AUTOSAR XML (schema 4-0-3)
package /AUTOSAR_Dem/ImplementationDataTypes
  4 x impl type, all with category=TYPE_REFERENCE, implementation-data-type=uint8:
    Dem_OperationCycleIdType: compu {0=DEM_OPCYC_IGNITION, 1=DEM_OPCYC_OBD_DCY, 2=DEM_OPCYC_POWER}, range raw 0..2
    Dem_IndicatorIdType: compu {0=DemConf_DemIndicator_DEM_INDICATOR_0}, range raw 0
    Dem_RatioIdType: range raw 0
    Dem_EnableConditionType: compu {0=DemConf_DemEnableCondition_DEM_SL_ECU_LEVEL}
package /AUTOSAR_Dem/SwComponentTypes
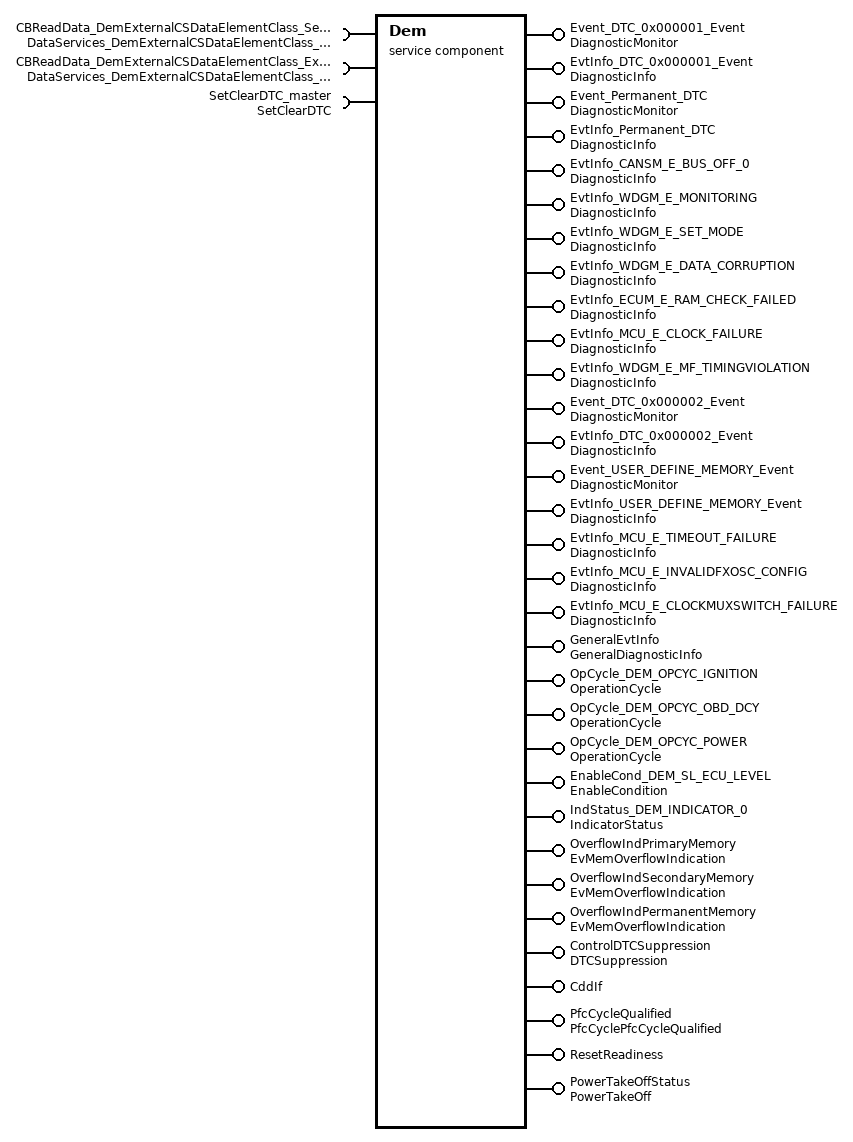
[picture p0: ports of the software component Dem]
  service sw component type Dem
    32 x provide port:
      Event_DTC_0x000001_Event: provided-interface=DiagnosticMonitor
        provided-com-specs:
          operation=SetEventStatus, queue-length=1
          operation=ResetEventStatus, queue-length=1
          operation=PrestoreFreezeFrame, queue-length=1
          operation=ClearPrestoredFreezeFrame, queue-length=1
          operation=SetEventDisabled, queue-length=1
          operation=ResetEventDebounceStatus, queue-length=1
      EvtInfo_DTC_0x000001_Event: provided-interface=DiagnosticInfo
        provided-com-specs:
          operation=GetEventStatus, queue-length=1
          operation=GetEventFailed, queue-length=1
          operation=GetEventTested, queue-length=1
          operation=GetDTCOfEvent, queue-length=1
          operation=GetFaultDetectionCounter, queue-length=1
          operation=GetEventFreezeFrameData, queue-length=1
          operation=GetEventExtendedDataRecord, queue-length=1
          operation=GetDebouncingOfEvent, queue-length=1
          operation=GetEventExtendedDataRecordEx, queue-length=1
          operation=GetEventFreezeFrameDataEx, queue-length=1
      Event_Permanent_DTC: provided-interface=DiagnosticMonitor
        provided-com-specs:
          operation=SetEventStatus, queue-length=1
          operation=ResetEventStatus, queue-length=1
          operation=PrestoreFreezeFrame, queue-length=1
          operation=ClearPrestoredFreezeFrame, queue-length=1
          operation=SetEventDisabled, queue-length=1
          operation=ResetEventDebounceStatus, queue-length=1
      EvtInfo_Permanent_DTC: provided-interface=DiagnosticInfo
        provided-com-specs:
          operation=GetEventStatus, queue-length=1
          operation=GetEventFailed, queue-length=1
          operation=GetEventTested, queue-length=1
          operation=GetDTCOfEvent, queue-length=1
          operation=GetFaultDetectionCounter, queue-length=1
          operation=GetEventFreezeFrameData, queue-length=1
          operation=GetEventExtendedDataRecord, queue-length=1
          operation=GetDebouncingOfEvent, queue-length=1
          operation=GetEventExtendedDataRecordEx, queue-length=1
          operation=GetEventFreezeFrameDataEx, queue-length=1
      EvtInfo_CANSM_E_BUS_OFF_0: provided-interface=DiagnosticInfo
        provided-com-specs:
          operation=GetEventStatus, queue-length=1
          operation=GetEventFailed, queue-length=1
          operation=GetEventTested, queue-length=1
          operation=GetDTCOfEvent, queue-length=1
          operation=GetFaultDetectionCounter, queue-length=1
          operation=GetEventFreezeFrameData, queue-length=1
          operation=GetEventExtendedDataRecord, queue-length=1
          operation=GetDebouncingOfEvent, queue-length=1
          operation=GetEventExtendedDataRecordEx, queue-length=1
          operation=GetEventFreezeFrameDataEx, queue-length=1
      EvtInfo_WDGM_E_MONITORING: provided-interface=DiagnosticInfo
        provided-com-specs:
          operation=GetEventStatus, queue-length=1
          operation=GetEventFailed, queue-length=1
          operation=GetEventTested, queue-length=1
          operation=GetDTCOfEvent, queue-length=1
          operation=GetFaultDetectionCounter, queue-length=1
          operation=GetEventFreezeFrameData, queue-length=1
          operation=GetEventExtendedDataRecord, queue-length=1
          operation=GetDebouncingOfEvent, queue-length=1
          operation=GetEventExtendedDataRecordEx, queue-length=1
          operation=GetEventFreezeFrameDataEx, queue-length=1
      EvtInfo_WDGM_E_SET_MODE: provided-interface=DiagnosticInfo
        provided-com-specs:
          operation=GetEventStatus, queue-length=1
          operation=GetEventFailed, queue-length=1
          operation=GetEventTested, queue-length=1
          operation=GetDTCOfEvent, queue-length=1
          operation=GetFaultDetectionCounter, queue-length=1
          operation=GetEventFreezeFrameData, queue-length=1
          operation=GetEventExtendedDataRecord, queue-length=1
          operation=GetDebouncingOfEvent, queue-length=1
          operation=GetEventExtendedDataRecordEx, queue-length=1
          operation=GetEventFreezeFrameDataEx, queue-length=1
      EvtInfo_WDGM_E_DATA_CORRUPTION: provided-interface=DiagnosticInfo
        provided-com-specs:
          operation=GetEventStatus, queue-length=1
          operation=GetEventFailed, queue-length=1
          operation=GetEventTested, queue-length=1
          operation=GetDTCOfEvent, queue-length=1
          operation=GetFaultDetectionCounter, queue-length=1
          operation=GetEventFreezeFrameData, queue-length=1
          operation=GetEventExtendedDataRecord, queue-length=1
          operation=GetDebouncingOfEvent, queue-length=1
          operation=GetEventExtendedDataRecordEx, queue-length=1
          operation=GetEventFreezeFrameDataEx, queue-length=1
      EvtInfo_ECUM_E_RAM_CHECK_FAILED: provided-interface=DiagnosticInfo
        provided-com-specs:
          operation=GetEventStatus, queue-length=1
          operation=GetEventFailed, queue-length=1
          operation=GetEventTested, queue-length=1
          operation=GetDTCOfEvent, queue-length=1
          operation=GetFaultDetectionCounter, queue-length=1
          operation=GetEventFreezeFrameData, queue-length=1
          operation=GetEventExtendedDataRecord, queue-length=1
          operation=GetDebouncingOfEvent, queue-length=1
          operation=GetEventExtendedDataRecordEx, queue-length=1
          operation=GetEventFreezeFrameDataEx, queue-length=1
      EvtInfo_MCU_E_CLOCK_FAILURE: provided-interface=DiagnosticInfo
        provided-com-specs:
          operation=GetEventStatus, queue-length=1
          operation=GetEventFailed, queue-length=1
          operation=GetEventTested, queue-length=1
          operation=GetDTCOfEvent, queue-length=1
          operation=GetFaultDetectionCounter, queue-length=1
          operation=GetEventFreezeFrameData, queue-length=1
          operation=GetEventExtendedDataRecord, queue-length=1
          operation=GetDebouncingOfEvent, queue-length=1
          operation=GetEventExtendedDataRecordEx, queue-length=1
          operation=GetEventFreezeFrameDataEx, queue-length=1
      EvtInfo_WDGM_E_MF_TIMINGVIOLATION: provided-interface=DiagnosticInfo
        provided-com-specs:
          operation=GetEventStatus, queue-length=1
          operation=GetEventFailed, queue-length=1
          operation=GetEventTested, queue-length=1
          operation=GetDTCOfEvent, queue-length=1
          operation=GetFaultDetectionCounter, queue-length=1
          operation=GetEventFreezeFrameData, queue-length=1
          operation=GetEventExtendedDataRecord, queue-length=1
          operation=GetDebouncingOfEvent, queue-length=1
          operation=GetEventExtendedDataRecordEx, queue-length=1
          operation=GetEventFreezeFrameDataEx, queue-length=1
      Event_DTC_0x000002_Event: provided-interface=DiagnosticMonitor
        provided-com-specs:
          operation=SetEventStatus, queue-length=1
          operation=ResetEventStatus, queue-length=1
          operation=PrestoreFreezeFrame, queue-length=1
          operation=ClearPrestoredFreezeFrame, queue-length=1
          operation=SetEventDisabled, queue-length=1
          operation=ResetEventDebounceStatus, queue-length=1
      EvtInfo_DTC_0x000002_Event: provided-interface=DiagnosticInfo
        provided-com-specs:
          operation=GetEventStatus, queue-length=1
          operation=GetEventFailed, queue-length=1
          operation=GetEventTested, queue-length=1
          operation=GetDTCOfEvent, queue-length=1
          operation=GetFaultDetectionCounter, queue-length=1
          operation=GetEventFreezeFrameData, queue-length=1
          operation=GetEventExtendedDataRecord, queue-length=1
          operation=GetDebouncingOfEvent, queue-length=1
          operation=GetEventExtendedDataRecordEx, queue-length=1
          operation=GetEventFreezeFrameDataEx, queue-length=1
      Event_USER_DEFINE_MEMORY_Event: provided-interface=DiagnosticMonitor
        provided-com-specs:
          operation=SetEventStatus, queue-length=1
          operation=ResetEventStatus, queue-length=1
          operation=PrestoreFreezeFrame, queue-length=1
          operation=ClearPrestoredFreezeFrame, queue-length=1
          operation=SetEventDisabled, queue-length=1
          operation=ResetEventDebounceStatus, queue-length=1
      EvtInfo_USER_DEFINE_MEMORY_Event: provided-interface=DiagnosticInfo
        provided-com-specs:
          operation=GetEventStatus, queue-length=1
          operation=GetEventFailed, queue-length=1
          operation=GetEventTested, queue-length=1
          operation=GetDTCOfEvent, queue-length=1
          operation=GetFaultDetectionCounter, queue-length=1
          operation=GetEventFreezeFrameData, queue-length=1
          operation=GetEventExtendedDataRecord, queue-length=1
          operation=GetDebouncingOfEvent, queue-length=1
          operation=GetEventExtendedDataRecordEx, queue-length=1
          operation=GetEventFreezeFrameDataEx, queue-length=1
      EvtInfo_MCU_E_TIMEOUT_FAILURE: provided-interface=DiagnosticInfo
        provided-com-specs:
          operation=GetEventStatus, queue-length=1
          operation=GetEventFailed, queue-length=1
          operation=GetEventTested, queue-length=1
          operation=GetDTCOfEvent, queue-length=1
          operation=GetFaultDetectionCounter, queue-length=1
          operation=GetEventFreezeFrameData, queue-length=1
          operation=GetEventExtendedDataRecord, queue-length=1
          operation=GetDebouncingOfEvent, queue-length=1
          operation=GetEventExtendedDataRecordEx, queue-length=1
          operation=GetEventFreezeFrameDataEx, queue-length=1
      EvtInfo_MCU_E_INVALIDFXOSC_CONFIG: provided-interface=DiagnosticInfo
        provided-com-specs:
          operation=GetEventStatus, queue-length=1
          operation=GetEventFailed, queue-length=1
          operation=GetEventTested, queue-length=1
          operation=GetDTCOfEvent, queue-length=1
          operation=GetFaultDetectionCounter, queue-length=1
          operation=GetEventFreezeFrameData, queue-length=1
          operation=GetEventExtendedDataRecord, queue-length=1
          operation=GetDebouncingOfEvent, queue-length=1
          operation=GetEventExtendedDataRecordEx, queue-length=1
          operation=GetEventFreezeFrameDataEx, queue-length=1
      EvtInfo_MCU_E_CLOCKMUXSWITCH_FAILURE: provided-interface=DiagnosticInfo
        provided-com-specs:
          operation=GetEventStatus, queue-length=1
          operation=GetEventFailed, queue-length=1
          operation=GetEventTested, queue-length=1
          operation=GetDTCOfEvent, queue-length=1
          operation=GetFaultDetectionCounter, queue-length=1
          operation=GetEventFreezeFrameData, queue-length=1
          operation=GetEventExtendedDataRecord, queue-length=1
          operation=GetDebouncingOfEvent, queue-length=1
          operation=GetEventExtendedDataRecordEx, queue-length=1
          operation=GetEventFreezeFrameDataEx, queue-length=1
      GeneralEvtInfo: provided-interface=GeneralDiagnosticInfo
        provided-com-specs:
          operation=GetEventStatus, queue-length=1
          operation=GetEventFailed, queue-length=1
          operation=GetEventTested, queue-length=1
          operation=GetDTCOfEvent, queue-length=1
          operation=GetFaultDetectionCounter, queue-length=1
          operation=GetEventFreezeFrameData, queue-length=1
          operation=GetEventExtendedDataRecord, queue-length=1
          operation=GetDebouncingOfEvent, queue-length=1
          operation=GetEventExtendedDataRecordEx, queue-length=1
          operation=GetEventFreezeFrameDataEx, queue-length=1
      OpCycle_DEM_OPCYC_IGNITION: provided-com-specs=[{operation=SetOperationCycleState, queue-length=1}, {operation=SetCycleQualified, queue-length=1}], provided-interface=OperationCycle
      OpCycle_DEM_OPCYC_OBD_DCY: provided-com-specs=[{operation=SetOperationCycleState, queue-length=1}, {operation=SetCycleQualified, queue-length=1}], provided-interface=OperationCycle
      OpCycle_DEM_OPCYC_POWER: provided-com-specs=[{operation=SetOperationCycleState, queue-length=1}, {operation=SetCycleQualified, queue-length=1}], provided-interface=OperationCycle
      EnableCond_DEM_SL_ECU_LEVEL: server-com-spec{operation=SetEnableCondition, queue-length=1}, provided-interface=EnableCondition
      IndStatus_DEM_INDICATOR_0: server-com-spec{operation=GetIndicatorStatus, queue-length=1}, provided-interface=IndicatorStatus
      OverflowIndPrimaryMemory: provided-interface=EvMemOverflowIndication
        provided-com-specs:
          operation=GetEventMemoryOverflow, queue-length=1
          operation=GetNumberOfEventMemoryEntries, queue-length=1
      OverflowIndSecondaryMemory: provided-interface=EvMemOverflowIndication
        provided-com-specs:
          operation=GetEventMemoryOverflow, queue-length=1
          operation=GetNumberOfEventMemoryEntries, queue-length=1
      OverflowIndPermanentMemory: server-com-spec{operation=GetEventMemoryOverflow, queue-length=1}, provided-interface=EvMemOverflowIndication
      ControlDTCSuppression: server-com-spec{operation=SetDTCSuppression, queue-length=1}, provided-interface=DTCSuppression
      CddIf: server-com-spec{operation=ClearDTC, queue-length=1}, provided-interface=CddIf
      PfcCycleQualified: provided-interface=PfcCyclePfcCycleQualified
        provided-com-specs:
          operation=SetPfcCycleSetPfcCycleQualified, queue-length=1
          operation=GetPfcCycleQualified, queue-length=1
      ResetReadiness: server-com-spec{operation=ResetReadiness, queue-length=1}, provided-interface=ResetReadiness
      PowerTakeOffStatus: server-com-spec{operation=SetPtoStatus, queue-length=1}, provided-interface=PowerTakeOff
    require port CBReadData_DemExternalCSDataElementClass_Session: required-interface=DataServices_DemExternalCSDataElementClass_Session
    require port CBReadData_DemExternalCSDataElementClass_ExtDataRec_0x01: required-interface=DataServices_DemExternalCSDataElementClass_ExtDataRec_0x01
    require port SetClearDTC_master: required-interface=SetClearDTC
    behavior DemIntBeh: handle-termination-and-restart=NO-SUPPORT, included-data-type-set=data-type=[Dem_EventStatusType, Dem_InitMonitorReasonType, Dem_IndicatorStatusType, Dem_EnableConditionType]
      194 x operation invoked event:
        EV_SetEventStatus_EvtDTC_0x000001_Event: start-on-event=RE_SetEventStatus, operation=Event_DTC_0x000001_Event.SetEventStatus
        EV_ResetEventStatus_EvtDTC_0x000001_Event: start-on-event=RE_ResetEventStatus, operation=Event_DTC_0x000001_Event.ResetEventStatus
        EV_PrestoreFreezeFrame_EvtDTC_0x000001_Event: start-on-event=RE_PrestoreFreezeFrame, operation=Event_DTC_0x000001_Event.PrestoreFreezeFrame
        EV_ClearPrestoredFF_EvtDTC_0x000001_Event: start-on-event=RE_ClearPrestoredFreezeFrame, operation=Event_DTC_0x000001_Event.ClearPrestoredFreezeFrame
        EV_SetEventDisabled_EvtDTC_0x000001_Event: start-on-event=RE_SetEventDisabled, operation=Event_DTC_0x000001_Event.SetEventDisabled
        EV_ResetEventDebounceStatus_EvtDTC_0x000001_Event: start-on-event=RE_ResetEventDebounceStatus, operation=Event_DTC_0x000001_Event.ResetEventDebounceStatus
        EV_GetEventStatus_EvtDTC_0x000001_Event: start-on-event=RE_GetEventStatus, operation=EvtInfo_DTC_0x000001_Event.GetEventStatus
        EV_GetEventFailed_EvtDTC_0x000001_Event: start-on-event=RE_GetEventFailed, operation=EvtInfo_DTC_0x000001_Event.GetEventFailed
        EV_GetEventTested_EvtDTC_0x000001_Event: start-on-event=RE_GetEventTested, operation=EvtInfo_DTC_0x000001_Event.GetEventTested
        EV_GetDTCOfEvent_EvtDTC_0x000001_Event: start-on-event=RE_GetDTCOfEvent, operation=EvtInfo_DTC_0x000001_Event.GetDTCOfEvent
        EV_GetFDC_EvtDTC_0x000001_Event: start-on-event=RE_GetFaultDetectionCounter, operation=EvtInfo_DTC_0x000001_Event.GetFaultDetectionCounter
        EV_GetEventFF_EvtDTC_0x000001_Event: start-on-event=RE_GetEventFreezeFrameData, operation=EvtInfo_DTC_0x000001_Event.GetEventFreezeFrameData
        EV_GetEventEDR_EvtDTC_0x000001_Event: start-on-event=RE_GetEventExtendedDataRecord, operation=EvtInfo_DTC_0x000001_Event.GetEventExtendedDataRecord
        EV_GetDebouncingOfEvent_EvtDTC_0x000001_Event: start-on-event=RE_GetDebouncingOfEvent, operation=EvtInfo_DTC_0x000001_Event.GetDebouncingOfEvent
        EV_GetEventFFEx_EvtDTC_0x000001_Event: start-on-event=RE_GetEventFreezeFrameDataEx, operation=EvtInfo_DTC_0x000001_Event.GetEventFreezeFrameDataEx
        EV_GetEventEDREx_EvtDTC_0x000001_Event: start-on-event=RE_GetEventExtendedDataRecordEx, operation=EvtInfo_DTC_0x000001_Event.GetEventExtendedDataRecordEx
        EV_SetEventStatus_EvtPermanent_DTC: start-on-event=RE_SetEventStatus, operation=Event_Permanent_DTC.SetEventStatus
        EV_ResetEventStatus_EvtPermanent_DTC: start-on-event=RE_ResetEventStatus, operation=Event_Permanent_DTC.ResetEventStatus
        EV_PrestoreFreezeFrame_EvtPermanent_DTC: start-on-event=RE_PrestoreFreezeFrame, operation=Event_Permanent_DTC.PrestoreFreezeFrame
        EV_ClearPrestoredFF_EvtPermanent_DTC: start-on-event=RE_ClearPrestoredFreezeFrame, operation=Event_Permanent_DTC.ClearPrestoredFreezeFrame
        EV_SetEventDisabled_EvtPermanent_DTC: start-on-event=RE_SetEventDisabled, operation=Event_Permanent_DTC.SetEventDisabled
        EV_ResetEventDebounceStatus_EvtPermanent_DTC: start-on-event=RE_ResetEventDebounceStatus, operation=Event_Permanent_DTC.ResetEventDebounceStatus
        EV_GetEventStatus_EvtPermanent_DTC: start-on-event=RE_GetEventStatus, operation=EvtInfo_Permanent_DTC.GetEventStatus
        EV_GetEventFailed_EvtPermanent_DTC: start-on-event=RE_GetEventFailed, operation=EvtInfo_Permanent_DTC.GetEventFailed
        EV_GetEventTested_EvtPermanent_DTC: start-on-event=RE_GetEventTested, operation=EvtInfo_Permanent_DTC.GetEventTested
        EV_GetDTCOfEvent_EvtPermanent_DTC: start-on-event=RE_GetDTCOfEvent, operation=EvtInfo_Permanent_DTC.GetDTCOfEvent
        EV_GetFDC_EvtPermanent_DTC: start-on-event=RE_GetFaultDetectionCounter, operation=EvtInfo_Permanent_DTC.GetFaultDetectionCounter
        EV_GetEventFF_EvtPermanent_DTC: start-on-event=RE_GetEventFreezeFrameData, operation=EvtInfo_Permanent_DTC.GetEventFreezeFrameData
        EV_GetEventEDR_EvtPermanent_DTC: start-on-event=RE_GetEventExtendedDataRecord, operation=EvtInfo_Permanent_DTC.GetEventExtendedDataRecord
        EV_GetDebouncingOfEvent_EvtPermanent_DTC: start-on-event=RE_GetDebouncingOfEvent, operation=EvtInfo_Permanent_DTC.GetDebouncingOfEvent
        EV_GetEventFFEx_EvtPermanent_DTC: start-on-event=RE_GetEventFreezeFrameDataEx, operation=EvtInfo_Permanent_DTC.GetEventFreezeFrameDataEx
        EV_GetEventEDREx_EvtPermanent_DTC: start-on-event=RE_GetEventExtendedDataRecordEx, operation=EvtInfo_Permanent_DTC.GetEventExtendedDataRecordEx
        EV_GetEventStatus_EvtCANSM_E_BUS_OFF_0: start-on-event=RE_GetEventStatus, operation=EvtInfo_CANSM_E_BUS_OFF_0.GetEventStatus
        EV_GetEventFailed_EvtCANSM_E_BUS_OFF_0: start-on-event=RE_GetEventFailed, operation=EvtInfo_CANSM_E_BUS_OFF_0.GetEventFailed
        EV_GetEventTested_EvtCANSM_E_BUS_OFF_0: start-on-event=RE_GetEventTested, operation=EvtInfo_CANSM_E_BUS_OFF_0.GetEventTested
        EV_GetDTCOfEvent_EvtCANSM_E_BUS_OFF_0: start-on-event=RE_GetDTCOfEvent, operation=EvtInfo_CANSM_E_BUS_OFF_0.GetDTCOfEvent
        EV_GetFDC_EvtCANSM_E_BUS_OFF_0: start-on-event=RE_GetFaultDetectionCounter, operation=EvtInfo_CANSM_E_BUS_OFF_0.GetFaultDetectionCounter
        EV_GetEventFF_EvtCANSM_E_BUS_OFF_0: start-on-event=RE_GetEventFreezeFrameData, operation=EvtInfo_CANSM_E_BUS_OFF_0.GetEventFreezeFrameData
        EV_GetEventEDR_EvtCANSM_E_BUS_OFF_0: start-on-event=RE_GetEventExtendedDataRecord, operation=EvtInfo_CANSM_E_BUS_OFF_0.GetEventExtendedDataRecord
        EV_GetDebouncingOfEvent_EvtCANSM_E_BUS_OFF_0: start-on-event=RE_GetDebouncingOfEvent, operation=EvtInfo_CANSM_E_BUS_OFF_0.GetDebouncingOfEvent
        EV_GetEventFFEx_EvtCANSM_E_BUS_OFF_0: start-on-event=RE_GetEventFreezeFrameDataEx, operation=EvtInfo_CANSM_E_BUS_OFF_0.GetEventFreezeFrameDataEx
        EV_GetEventEDREx_EvtCANSM_E_BUS_OFF_0: start-on-event=RE_GetEventExtendedDataRecordEx, operation=EvtInfo_CANSM_E_BUS_OFF_0.GetEventExtendedDataRecordEx
        EV_GetEventStatus_EvtWDGM_E_MONITORING: start-on-event=RE_GetEventStatus, operation=EvtInfo_WDGM_E_MONITORING.GetEventStatus
        EV_GetEventFailed_EvtWDGM_E_MONITORING: start-on-event=RE_GetEventFailed, operation=EvtInfo_WDGM_E_MONITORING.GetEventFailed
        EV_GetEventTested_EvtWDGM_E_MONITORING: start-on-event=RE_GetEventTested, operation=EvtInfo_WDGM_E_MONITORING.GetEventTested
        EV_GetDTCOfEvent_EvtWDGM_E_MONITORING: start-on-event=RE_GetDTCOfEvent, operation=EvtInfo_WDGM_E_MONITORING.GetDTCOfEvent
        EV_GetFDC_EvtWDGM_E_MONITORING: start-on-event=RE_GetFaultDetectionCounter, operation=EvtInfo_WDGM_E_MONITORING.GetFaultDetectionCounter
        EV_GetEventFF_EvtWDGM_E_MONITORING: start-on-event=RE_GetEventFreezeFrameData, operation=EvtInfo_WDGM_E_MONITORING.GetEventFreezeFrameData
        EV_GetEventEDR_EvtWDGM_E_MONITORING: start-on-event=RE_GetEventExtendedDataRecord, operation=EvtInfo_WDGM_E_MONITORING.GetEventExtendedDataRecord
        EV_GetDebouncingOfEvent_EvtWDGM_E_MONITORING: start-on-event=RE_GetDebouncingOfEvent, operation=EvtInfo_WDGM_E_MONITORING.GetDebouncingOfEvent
        EV_GetEventFFEx_EvtWDGM_E_MONITORING: start-on-event=RE_GetEventFreezeFrameDataEx, operation=EvtInfo_WDGM_E_MONITORING.GetEventFreezeFrameDataEx
        EV_GetEventEDREx_EvtWDGM_E_MONITORING: start-on-event=RE_GetEventExtendedDataRecordEx, operation=EvtInfo_WDGM_E_MONITORING.GetEventExtendedDataRecordEx
        EV_GetEventStatus_EvtWDGM_E_SET_MODE: start-on-event=RE_GetEventStatus, operation=EvtInfo_WDGM_E_SET_MODE.GetEventStatus
        EV_GetEventFailed_EvtWDGM_E_SET_MODE: start-on-event=RE_GetEventFailed, operation=EvtInfo_WDGM_E_SET_MODE.GetEventFailed
        EV_GetEventTested_EvtWDGM_E_SET_MODE: start-on-event=RE_GetEventTested, operation=EvtInfo_WDGM_E_SET_MODE.GetEventTested
        EV_GetDTCOfEvent_EvtWDGM_E_SET_MODE: start-on-event=RE_GetDTCOfEvent, operation=EvtInfo_WDGM_E_SET_MODE.GetDTCOfEvent
        EV_GetFDC_EvtWDGM_E_SET_MODE: start-on-event=RE_GetFaultDetectionCounter, operation=EvtInfo_WDGM_E_SET_MODE.GetFaultDetectionCounter
        EV_GetEventFF_EvtWDGM_E_SET_MODE: start-on-event=RE_GetEventFreezeFrameData, operation=EvtInfo_WDGM_E_SET_MODE.GetEventFreezeFrameData
        EV_GetEventEDR_EvtWDGM_E_SET_MODE: start-on-event=RE_GetEventExtendedDataRecord, operation=EvtInfo_WDGM_E_SET_MODE.GetEventExtendedDataRecord
        EV_GetDebouncingOfEvent_EvtWDGM_E_SET_MODE: start-on-event=RE_GetDebouncingOfEvent, operation=EvtInfo_WDGM_E_SET_MODE.GetDebouncingOfEvent
        EV_GetEventFFEx_EvtWDGM_E_SET_MODE: start-on-event=RE_GetEventFreezeFrameDataEx, operation=EvtInfo_WDGM_E_SET_MODE.GetEventFreezeFrameDataEx
        EV_GetEventEDREx_EvtWDGM_E_SET_MODE: start-on-event=RE_GetEventExtendedDataRecordEx, operation=EvtInfo_WDGM_E_SET_MODE.GetEventExtendedDataRecordEx
        EV_GetEventStatus_EvtWDGM_E_DATA_CORRUPTION: start-on-event=RE_GetEventStatus, operation=EvtInfo_WDGM_E_DATA_CORRUPTION.GetEventStatus
        EV_GetEventFailed_EvtWDGM_E_DATA_CORRUPTION: start-on-event=RE_GetEventFailed, operation=EvtInfo_WDGM_E_DATA_CORRUPTION.GetEventFailed
        EV_GetEventTested_EvtWDGM_E_DATA_CORRUPTION: start-on-event=RE_GetEventTested, operation=EvtInfo_WDGM_E_DATA_CORRUPTION.GetEventTested
        EV_GetDTCOfEvent_EvtWDGM_E_DATA_CORRUPTION: start-on-event=RE_GetDTCOfEvent, operation=EvtInfo_WDGM_E_DATA_CORRUPTION.GetDTCOfEvent
        EV_GetFDC_EvtWDGM_E_DATA_CORRUPTION: start-on-event=RE_GetFaultDetectionCounter, operation=EvtInfo_WDGM_E_DATA_CORRUPTION.GetFaultDetectionCounter
        EV_GetEventFF_EvtWDGM_E_DATA_CORRUPTION: start-on-event=RE_GetEventFreezeFrameData, operation=EvtInfo_WDGM_E_DATA_CORRUPTION.GetEventFreezeFrameData
        EV_GetEventEDR_EvtWDGM_E_DATA_CORRUPTION: start-on-event=RE_GetEventExtendedDataRecord, operation=EvtInfo_WDGM_E_DATA_CORRUPTION.GetEventExtendedDataRecord
        EV_GetDebouncingOfEvent_EvtWDGM_E_DATA_CORRUPTION: start-on-event=RE_GetDebouncingOfEvent, operation=EvtInfo_WDGM_E_DATA_CORRUPTION.GetDebouncingOfEvent
        EV_GetEventFFEx_EvtWDGM_E_DATA_CORRUPTION: start-on-event=RE_GetEventFreezeFrameDataEx, operation=EvtInfo_WDGM_E_DATA_CORRUPTION.GetEventFreezeFrameDataEx
        EV_GetEventEDREx_EvtWDGM_E_DATA_CORRUPTION: start-on-event=RE_GetEventExtendedDataRecordEx, operation=EvtInfo_WDGM_E_DATA_CORRUPTION.GetEventExtendedDataRecordEx
        EV_GetEventStatus_EvtECUM_E_RAM_CHECK_FAILED: start-on-event=RE_GetEventStatus, operation=EvtInfo_ECUM_E_RAM_CHECK_FAILED.GetEventStatus
        EV_GetEventFailed_EvtECUM_E_RAM_CHECK_FAILED: start-on-event=RE_GetEventFailed, operation=EvtInfo_ECUM_E_RAM_CHECK_FAILED.GetEventFailed
        EV_GetEventTested_EvtECUM_E_RAM_CHECK_FAILED: start-on-event=RE_GetEventTested, operation=EvtInfo_ECUM_E_RAM_CHECK_FAILED.GetEventTested
        EV_GetDTCOfEvent_EvtECUM_E_RAM_CHECK_FAILED: start-on-event=RE_GetDTCOfEvent, operation=EvtInfo_ECUM_E_RAM_CHECK_FAILED.GetDTCOfEvent
        EV_GetFDC_EvtECUM_E_RAM_CHECK_FAILED: start-on-event=RE_GetFaultDetectionCounter, operation=EvtInfo_ECUM_E_RAM_CHECK_FAILED.GetFaultDetectionCounter
        EV_GetEventFF_EvtECUM_E_RAM_CHECK_FAILED: start-on-event=RE_GetEventFreezeFrameData, operation=EvtInfo_ECUM_E_RAM_CHECK_FAILED.GetEventFreezeFrameData
        EV_GetEventEDR_EvtECUM_E_RAM_CHECK_FAILED: start-on-event=RE_GetEventExtendedDataRecord, operation=EvtInfo_ECUM_E_RAM_CHECK_FAILED.GetEventExtendedDataRecord
        EV_GetDebouncingOfEvent_EvtECUM_E_RAM_CHECK_FAILED: start-on-event=RE_GetDebouncingOfEvent, operation=EvtInfo_ECUM_E_RAM_CHECK_FAILED.GetDebouncingOfEvent
        EV_GetEventFFEx_EvtECUM_E_RAM_CHECK_FAILED: start-on-event=RE_GetEventFreezeFrameDataEx, operation=EvtInfo_ECUM_E_RAM_CHECK_FAILED.GetEventFreezeFrameDataEx
        EV_GetEventEDREx_EvtECUM_E_RAM_CHECK_FAILED: start-on-event=RE_GetEventExtendedDataRecordEx, operation=EvtInfo_ECUM_E_RAM_CHECK_FAILED.GetEventExtendedDataRecordEx
        EV_GetEventStatus_EvtMCU_E_CLOCK_FAILURE: start-on-event=RE_GetEventStatus, operation=EvtInfo_MCU_E_CLOCK_FAILURE.GetEventStatus
        EV_GetEventFailed_EvtMCU_E_CLOCK_FAILURE: start-on-event=RE_GetEventFailed, operation=EvtInfo_MCU_E_CLOCK_FAILURE.GetEventFailed
        EV_GetEventTested_EvtMCU_E_CLOCK_FAILURE: start-on-event=RE_GetEventTested, operation=EvtInfo_MCU_E_CLOCK_FAILURE.GetEventTested
        EV_GetDTCOfEvent_EvtMCU_E_CLOCK_FAILURE: start-on-event=RE_GetDTCOfEvent, operation=EvtInfo_MCU_E_CLOCK_FAILURE.GetDTCOfEvent
        EV_GetFDC_EvtMCU_E_CLOCK_FAILURE: start-on-event=RE_GetFaultDetectionCounter, operation=EvtInfo_MCU_E_CLOCK_FAILURE.GetFaultDetectionCounter
        EV_GetEventFF_EvtMCU_E_CLOCK_FAILURE: start-on-event=RE_GetEventFreezeFrameData, operation=EvtInfo_MCU_E_CLOCK_FAILURE.GetEventFreezeFrameData
        EV_GetEventEDR_EvtMCU_E_CLOCK_FAILURE: start-on-event=RE_GetEventExtendedDataRecord, operation=EvtInfo_MCU_E_CLOCK_FAILURE.GetEventExtendedDataRecord
        EV_GetDebouncingOfEvent_EvtMCU_E_CLOCK_FAILURE: start-on-event=RE_GetDebouncingOfEvent, operation=EvtInfo_MCU_E_CLOCK_FAILURE.GetDebouncingOfEvent
        EV_GetEventFFEx_EvtMCU_E_CLOCK_FAILURE: start-on-event=RE_GetEventFreezeFrameDataEx, operation=EvtInfo_MCU_E_CLOCK_FAILURE.GetEventFreezeFrameDataEx
        EV_GetEventEDREx_EvtMCU_E_CLOCK_FAILURE: start-on-event=RE_GetEventExtendedDataRecordEx, operation=EvtInfo_MCU_E_CLOCK_FAILURE.GetEventExtendedDataRecordEx
        EV_GetEventStatus_EvtWDGM_E_MF_TIMINGVIOLATION: start-on-event=RE_GetEventStatus, operation=EvtInfo_WDGM_E_MF_TIMINGVIOLATION.GetEventStatus
        EV_GetEventFailed_EvtWDGM_E_MF_TIMINGVIOLATION: start-on-event=RE_GetEventFailed, operation=EvtInfo_WDGM_E_MF_TIMINGVIOLATION.GetEventFailed
        EV_GetEventTested_EvtWDGM_E_MF_TIMINGVIOLATION: start-on-event=RE_GetEventTested, operation=EvtInfo_WDGM_E_MF_TIMINGVIOLATION.GetEventTested
        EV_GetDTCOfEvent_EvtWDGM_E_MF_TIMINGVIOLATION: start-on-event=RE_GetDTCOfEvent, operation=EvtInfo_WDGM_E_MF_TIMINGVIOLATION.GetDTCOfEvent
        EV_GetFDC_EvtWDGM_E_MF_TIMINGVIOLATION: start-on-event=RE_GetFaultDetectionCounter, operation=EvtInfo_WDGM_E_MF_TIMINGVIOLATION.GetFaultDetectionCounter
        EV_GetEventFF_EvtWDGM_E_MF_TIMINGVIOLATION: start-on-event=RE_GetEventFreezeFrameData, operation=EvtInfo_WDGM_E_MF_TIMINGVIOLATION.GetEventFreezeFrameData
        EV_GetEventEDR_EvtWDGM_E_MF_TIMINGVIOLATION: start-on-event=RE_GetEventExtendedDataRecord, operation=EvtInfo_WDGM_E_MF_TIMINGVIOLATION.GetEventExtendedDataRecord
        EV_GetDebouncingOfEvent_EvtWDGM_E_MF_TIMINGVIOLATION: start-on-event=RE_GetDebouncingOfEvent, operation=EvtInfo_WDGM_E_MF_TIMINGVIOLATION.GetDebouncingOfEvent
        EV_GetEventFFEx_EvtWDGM_E_MF_TIMINGVIOLATION: start-on-event=RE_GetEventFreezeFrameDataEx, operation=EvtInfo_WDGM_E_MF_TIMINGVIOLATION.GetEventFreezeFrameDataEx
        EV_GetEventEDREx_EvtWDGM_E_MF_TIMINGVIOLATION: start-on-event=RE_GetEventExtendedDataRecordEx, operation=EvtInfo_WDGM_E_MF_TIMINGVIOLATION.GetEventExtendedDataRecordEx
        EV_SetEventStatus_EvtDTC_0x000002_Event: start-on-event=RE_SetEventStatus, operation=Event_DTC_0x000002_Event.SetEventStatus
        EV_ResetEventStatus_EvtDTC_0x000002_Event: start-on-event=RE_ResetEventStatus, operation=Event_DTC_0x000002_Event.ResetEventStatus
        EV_PrestoreFreezeFrame_EvtDTC_0x000002_Event: start-on-event=RE_PrestoreFreezeFrame, operation=Event_DTC_0x000002_Event.PrestoreFreezeFrame
        EV_ClearPrestoredFF_EvtDTC_0x000002_Event: start-on-event=RE_ClearPrestoredFreezeFrame, operation=Event_DTC_0x000002_Event.ClearPrestoredFreezeFrame
        EV_SetEventDisabled_EvtDTC_0x000002_Event: start-on-event=RE_SetEventDisabled, operation=Event_DTC_0x000002_Event.SetEventDisabled
        EV_ResetEventDebounceStatus_EvtDTC_0x000002_Event: start-on-event=RE_ResetEventDebounceStatus, operation=Event_DTC_0x000002_Event.ResetEventDebounceStatus
        EV_GetEventStatus_EvtDTC_0x000002_Event: start-on-event=RE_GetEventStatus, operation=EvtInfo_DTC_0x000002_Event.GetEventStatus
        EV_GetEventFailed_EvtDTC_0x000002_Event: start-on-event=RE_GetEventFailed, operation=EvtInfo_DTC_0x000002_Event.GetEventFailed
        EV_GetEventTested_EvtDTC_0x000002_Event: start-on-event=RE_GetEventTested, operation=EvtInfo_DTC_0x000002_Event.GetEventTested
        EV_GetDTCOfEvent_EvtDTC_0x000002_Event: start-on-event=RE_GetDTCOfEvent, operation=EvtInfo_DTC_0x000002_Event.GetDTCOfEvent
        EV_GetFDC_EvtDTC_0x000002_Event: start-on-event=RE_GetFaultDetectionCounter, operation=EvtInfo_DTC_0x000002_Event.GetFaultDetectionCounter
        EV_GetEventFF_EvtDTC_0x000002_Event: start-on-event=RE_GetEventFreezeFrameData, operation=EvtInfo_DTC_0x000002_Event.GetEventFreezeFrameData
        EV_GetEventEDR_EvtDTC_0x000002_Event: start-on-event=RE_GetEventExtendedDataRecord, operation=EvtInfo_DTC_0x000002_Event.GetEventExtendedDataRecord
        EV_GetDebouncingOfEvent_EvtDTC_0x000002_Event: start-on-event=RE_GetDebouncingOfEvent, operation=EvtInfo_DTC_0x000002_Event.GetDebouncingOfEvent
        EV_GetEventFFEx_EvtDTC_0x000002_Event: start-on-event=RE_GetEventFreezeFrameDataEx, operation=EvtInfo_DTC_0x000002_Event.GetEventFreezeFrameDataEx
        EV_GetEventEDREx_EvtDTC_0x000002_Event: start-on-event=RE_GetEventExtendedDataRecordEx, operation=EvtInfo_DTC_0x000002_Event.GetEventExtendedDataRecordEx
        EV_SetEventStatus_EvtUSER_DEFINE_MEMORY_Event: start-on-event=RE_SetEventStatus, operation=Event_USER_DEFINE_MEMORY_Event.SetEventStatus
        EV_ResetEventStatus_EvtUSER_DEFINE_MEMORY_Event: start-on-event=RE_ResetEventStatus, operation=Event_USER_DEFINE_MEMORY_Event.ResetEventStatus
        EV_PrestoreFreezeFrame_EvtUSER_DEFINE_MEMORY_Event: start-on-event=RE_PrestoreFreezeFrame, operation=Event_USER_DEFINE_MEMORY_Event.PrestoreFreezeFrame
        EV_ClearPrestoredFF_EvtUSER_DEFINE_MEMORY_Event: start-on-event=RE_ClearPrestoredFreezeFrame, operation=Event_USER_DEFINE_MEMORY_Event.ClearPrestoredFreezeFrame
        EV_SetEventDisabled_EvtUSER_DEFINE_MEMORY_Event: start-on-event=RE_SetEventDisabled, operation=Event_USER_DEFINE_MEMORY_Event.SetEventDisabled
        EV_ResetEventDebounceStatus_EvtUSER_DEFINE_MEMORY_Event: start-on-event=RE_ResetEventDebounceStatus, operation=Event_USER_DEFINE_MEMORY_Event.ResetEventDebounceStatus
        EV_GetEventStatus_EvtUSER_DEFINE_MEMORY_Event: start-on-event=RE_GetEventStatus, operation=EvtInfo_USER_DEFINE_MEMORY_Event.GetEventStatus
        EV_GetEventFailed_EvtUSER_DEFINE_MEMORY_Event: start-on-event=RE_GetEventFailed, operation=EvtInfo_USER_DEFINE_MEMORY_Event.GetEventFailed
        EV_GetEventTested_EvtUSER_DEFINE_MEMORY_Event: start-on-event=RE_GetEventTested, operation=EvtInfo_USER_DEFINE_MEMORY_Event.GetEventTested
        EV_GetDTCOfEvent_EvtUSER_DEFINE_MEMORY_Event: start-on-event=RE_GetDTCOfEvent, operation=EvtInfo_USER_DEFINE_MEMORY_Event.GetDTCOfEvent
        EV_GetFDC_EvtUSER_DEFINE_MEMORY_Event: start-on-event=RE_GetFaultDetectionCounter, operation=EvtInfo_USER_DEFINE_MEMORY_Event.GetFaultDetectionCounter
        EV_GetEventFF_EvtUSER_DEFINE_MEMORY_Event: start-on-event=RE_GetEventFreezeFrameData, operation=EvtInfo_USER_DEFINE_MEMORY_Event.GetEventFreezeFrameData
        EV_GetEventEDR_EvtUSER_DEFINE_MEMORY_Event: start-on-event=RE_GetEventExtendedDataRecord, operation=EvtInfo_USER_DEFINE_MEMORY_Event.GetEventExtendedDataRecord
        EV_GetDebouncingOfEvent_EvtUSER_DEFINE_MEMORY_Event: start-on-event=RE_GetDebouncingOfEvent, operation=EvtInfo_USER_DEFINE_MEMORY_Event.GetDebouncingOfEvent
        EV_GetEventFFEx_EvtUSER_DEFINE_MEMORY_Event: start-on-event=RE_GetEventFreezeFrameDataEx, operation=EvtInfo_USER_DEFINE_MEMORY_Event.GetEventFreezeFrameDataEx
        EV_GetEventEDREx_EvtUSER_DEFINE_MEMORY_Event: start-on-event=RE_GetEventExtendedDataRecordEx, operation=EvtInfo_USER_DEFINE_MEMORY_Event.GetEventExtendedDataRecordEx
        EV_GetEventStatus_EvtMCU_E_TIMEOUT_FAILURE: start-on-event=RE_GetEventStatus, operation=EvtInfo_MCU_E_TIMEOUT_FAILURE.GetEventStatus
        EV_GetEventFailed_EvtMCU_E_TIMEOUT_FAILURE: start-on-event=RE_GetEventFailed, operation=EvtInfo_MCU_E_TIMEOUT_FAILURE.GetEventFailed
        EV_GetEventTested_EvtMCU_E_TIMEOUT_FAILURE: start-on-event=RE_GetEventTested, operation=EvtInfo_MCU_E_TIMEOUT_FAILURE.GetEventTested
        EV_GetDTCOfEvent_EvtMCU_E_TIMEOUT_FAILURE: start-on-event=RE_GetDTCOfEvent, operation=EvtInfo_MCU_E_TIMEOUT_FAILURE.GetDTCOfEvent
        EV_GetFDC_EvtMCU_E_TIMEOUT_FAILURE: start-on-event=RE_GetFaultDetectionCounter, operation=EvtInfo_MCU_E_TIMEOUT_FAILURE.GetFaultDetectionCounter
        EV_GetEventFF_EvtMCU_E_TIMEOUT_FAILURE: start-on-event=RE_GetEventFreezeFrameData, operation=EvtInfo_MCU_E_TIMEOUT_FAILURE.GetEventFreezeFrameData
        EV_GetEventEDR_EvtMCU_E_TIMEOUT_FAILURE: start-on-event=RE_GetEventExtendedDataRecord, operation=EvtInfo_MCU_E_TIMEOUT_FAILURE.GetEventExtendedDataRecord
        EV_GetDebouncingOfEvent_EvtMCU_E_TIMEOUT_FAILURE: start-on-event=RE_GetDebouncingOfEvent, operation=EvtInfo_MCU_E_TIMEOUT_FAILURE.GetDebouncingOfEvent
        EV_GetEventFFEx_EvtMCU_E_TIMEOUT_FAILURE: start-on-event=RE_GetEventFreezeFrameDataEx, operation=EvtInfo_MCU_E_TIMEOUT_FAILURE.GetEventFreezeFrameDataEx
        EV_GetEventEDREx_EvtMCU_E_TIMEOUT_FAILURE: start-on-event=RE_GetEventExtendedDataRecordEx, operation=EvtInfo_MCU_E_TIMEOUT_FAILURE.GetEventExtendedDataRecordEx
        EV_GetEventStatus_EvtMCU_E_INVALIDFXOSC_CONFIG: start-on-event=RE_GetEventStatus, operation=EvtInfo_MCU_E_INVALIDFXOSC_CONFIG.GetEventStatus
        EV_GetEventFailed_EvtMCU_E_INVALIDFXOSC_CONFIG: start-on-event=RE_GetEventFailed, operation=EvtInfo_MCU_E_INVALIDFXOSC_CONFIG.GetEventFailed
        EV_GetEventTested_EvtMCU_E_INVALIDFXOSC_CONFIG: start-on-event=RE_GetEventTested, operation=EvtInfo_MCU_E_INVALIDFXOSC_CONFIG.GetEventTested
        EV_GetDTCOfEvent_EvtMCU_E_INVALIDFXOSC_CONFIG: start-on-event=RE_GetDTCOfEvent, operation=EvtInfo_MCU_E_INVALIDFXOSC_CONFIG.GetDTCOfEvent
        EV_GetFDC_EvtMCU_E_INVALIDFXOSC_CONFIG: start-on-event=RE_GetFaultDetectionCounter, operation=EvtInfo_MCU_E_INVALIDFXOSC_CONFIG.GetFaultDetectionCounter
        EV_GetEventFF_EvtMCU_E_INVALIDFXOSC_CONFIG: start-on-event=RE_GetEventFreezeFrameData, operation=EvtInfo_MCU_E_INVALIDFXOSC_CONFIG.GetEventFreezeFrameData
        EV_GetEventEDR_EvtMCU_E_INVALIDFXOSC_CONFIG: start-on-event=RE_GetEventExtendedDataRecord, operation=EvtInfo_MCU_E_INVALIDFXOSC_CONFIG.GetEventExtendedDataRecord
        EV_GetDebouncingOfEvent_EvtMCU_E_INVALIDFXOSC_CONFIG: start-on-event=RE_GetDebouncingOfEvent, operation=EvtInfo_MCU_E_INVALIDFXOSC_CONFIG.GetDebouncingOfEvent
        EV_GetEventFFEx_EvtMCU_E_INVALIDFXOSC_CONFIG: start-on-event=RE_GetEventFreezeFrameDataEx, operation=EvtInfo_MCU_E_INVALIDFXOSC_CONFIG.GetEventFreezeFrameDataEx
        EV_GetEventEDREx_EvtMCU_E_INVALIDFXOSC_CONFIG: start-on-event=RE_GetEventExtendedDataRecordEx, operation=EvtInfo_MCU_E_INVALIDFXOSC_CONFIG.GetEventExtendedDataRecordEx
        EV_GetEventStatus_EvtMCU_E_CLOCKMUXSWITCH_FAILURE: start-on-event=RE_GetEventStatus, operation=EvtInfo_MCU_E_CLOCKMUXSWITCH_FAILURE.GetEventStatus
        EV_GetEventFailed_EvtMCU_E_CLOCKMUXSWITCH_FAILURE: start-on-event=RE_GetEventFailed, operation=EvtInfo_MCU_E_CLOCKMUXSWITCH_FAILURE.GetEventFailed
        EV_GetEventTested_EvtMCU_E_CLOCKMUXSWITCH_FAILURE: start-on-event=RE_GetEventTested, operation=EvtInfo_MCU_E_CLOCKMUXSWITCH_FAILURE.GetEventTested
        EV_GetDTCOfEvent_EvtMCU_E_CLOCKMUXSWITCH_FAILURE: start-on-event=RE_GetDTCOfEvent, operation=EvtInfo_MCU_E_CLOCKMUXSWITCH_FAILURE.GetDTCOfEvent
        EV_GetFDC_EvtMCU_E_CLOCKMUXSWITCH_FAILURE: start-on-event=RE_GetFaultDetectionCounter, operation=EvtInfo_MCU_E_CLOCKMUXSWITCH_FAILURE.GetFaultDetectionCounter
        EV_GetEventFF_EvtMCU_E_CLOCKMUXSWITCH_FAILURE: start-on-event=RE_GetEventFreezeFrameData, operation=EvtInfo_MCU_E_CLOCKMUXSWITCH_FAILURE.GetEventFreezeFrameData
        EV_GetEventEDR_EvtMCU_E_CLOCKMUXSWITCH_FAILURE: start-on-event=RE_GetEventExtendedDataRecord, operation=EvtInfo_MCU_E_CLOCKMUXSWITCH_FAILURE.GetEventExtendedDataRecord
        EV_GetDebouncingOfEvent_EvtMCU_E_CLOCKMUXSWITCH_FAILURE: start-on-event=RE_GetDebouncingOfEvent, operation=EvtInfo_MCU_E_CLOCKMUXSWITCH_FAILURE.GetDebouncingOfEvent
        EV_GetEventFFEx_EvtMCU_E_CLOCKMUXSWITCH_FAILURE: start-on-event=RE_GetEventFreezeFrameDataEx, operation=EvtInfo_MCU_E_CLOCKMUXSWITCH_FAILURE.GetEventFreezeFrameDataEx
        EV_GetEventEDREx_EvtMCU_E_CLOCKMUXSWITCH_FAILURE: start-on-event=RE_GetEventExtendedDataRecordEx, operation=EvtInfo_MCU_E_CLOCKMUXSWITCH_FAILURE.GetEventExtendedDataRecordEx
        EV_GetEventStatus_GeneralEvt: start-on-event=RE_GetEventStatus, operation=GeneralEvtInfo.GetEventStatus
        EV_GetEventFailed_GeneralEvt: start-on-event=RE_GetEventFailed, operation=GeneralEvtInfo.GetEventFailed
        EV_GetEventTested_GeneralEvt: start-on-event=RE_GetEventTested, operation=GeneralEvtInfo.GetEventTested
        EV_GetDTCOfEvent_GeneralEvt: start-on-event=RE_GetDTCOfEvent, operation=GeneralEvtInfo.GetDTCOfEvent
        EV_GetFDC_GeneralEvt: start-on-event=RE_GetFaultDetectionCounter, operation=GeneralEvtInfo.GetFaultDetectionCounter
        EV_GetEventFF_GeneralEvt: start-on-event=RE_GetEventFreezeFrameData, operation=GeneralEvtInfo.GetEventFreezeFrameData
        EV_GetEventEDR_GeneralEvt: start-on-event=RE_GetEventExtendedDataRecord, operation=GeneralEvtInfo.GetEventExtendedDataRecord
        EV_GetDebouncingOfEvent_GeneralEvt: start-on-event=RE_GetDebouncingOfEvent, operation=GeneralEvtInfo.GetDebouncingOfEvent
        EV_GetEventFFEx_GeneralEvt: start-on-event=RE_GetEventFreezeFrameDataEx, operation=GeneralEvtInfo.GetEventFreezeFrameDataEx
        EV_GetEventEDREx_GeneralEvt: start-on-event=RE_GetEventExtendedDataRecordEx, operation=GeneralEvtInfo.GetEventExtendedDataRecordEx
        EV_SetOperationCycleState_OpCycDEM_OPCYC_IGNITION: start-on-event=RE_SetOperationCycleState, operation=OpCycle_DEM_OPCYC_IGNITION.SetOperationCycleState
        EV_SetCycleQualified_OpCycDEM_OPCYC_IGNITION: start-on-event=RE_SetCycleQualified, operation=OpCycle_DEM_OPCYC_IGNITION.SetCycleQualified
        EV_SetOperationCycleState_OpCycDEM_OPCYC_OBD_DCY: start-on-event=RE_SetOperationCycleState, operation=OpCycle_DEM_OPCYC_OBD_DCY.SetOperationCycleState
        EV_SetCycleQualified_OpCycDEM_OPCYC_OBD_DCY: start-on-event=RE_SetCycleQualified, operation=OpCycle_DEM_OPCYC_OBD_DCY.SetCycleQualified
        EV_SetOperationCycleState_OpCycDEM_OPCYC_POWER: start-on-event=RE_SetOperationCycleState, operation=OpCycle_DEM_OPCYC_POWER.SetOperationCycleState
        EV_SetCycleQualified_OpCycDEM_OPCYC_POWER: start-on-event=RE_SetCycleQualified, operation=OpCycle_DEM_OPCYC_POWER.SetCycleQualified
        EV_SetEnableCondition_EnCondDEM_SL_ECU_LEVEL: start-on-event=RE_SetEnableCondition, operation=EnableCond_DEM_SL_ECU_LEVEL.SetEnableCondition
        EV_GetIndicatorStatus_IndStDEM_INDICATOR_0: start-on-event=RE_GetIndicatorStatus, operation=IndStatus_DEM_INDICATOR_0.GetIndicatorStatus
        EV_GetEventMemoryOverflow_Primary: start-on-event=RE_GetEventMemoryOverflow, operation=OverflowIndPrimaryMemory.GetEventMemoryOverflow
        EV_GetNumberOfEventMemoryEntries_Primary: start-on-event=RE_GetNumberOfEventMemoryEntries, operation=OverflowIndPrimaryMemory.GetNumberOfEventMemoryEntries
        EV_GetEventMemoryOverflow_Secondary: start-on-event=RE_GetEventMemoryOverflow, operation=OverflowIndSecondaryMemory.GetEventMemoryOverflow
        EV_GetNumberOfEventMemoryEntries_Secondary: start-on-event=RE_GetNumberOfEventMemoryEntries, operation=OverflowIndSecondaryMemory.GetNumberOfEventMemoryEntries
        EV_GetEventMemoryOverflow_Permanent: start-on-event=RE_GetEventMemoryOverflow, operation=OverflowIndPermanentMemory.GetEventMemoryOverflow
        EV_GetNumberOfEventMemoryEntries_Permanent: start-on-event=RE_GetNumberOfEventMemoryEntries, operation=OverflowIndPermanentMemory.GetNumberOfEventMemoryEntries
        EV_SetDTCSuppression: start-on-event=RE_SetDTCSuppression, operation=ControlDTCSuppression.SetDTCSuppression
        EV_ClearDTC: start-on-event=RE_CddIfClearDTC, operation=CddIf.ClearDTC
        EV_SetPfcCycleQualified: start-on-event=RE_SetPfcCycleQualified, operation=PfcCycleQualified.SetPfcCycleSetPfcCycleQualified
        EV_GetPfcCycleQualified: start-on-event=RE_GetPfcCycleQualified, operation=PfcCycleQualified.GetPfcCycleQualified
        EV_ResetReadiness: start-on-event=RE_ResetReadiness, operation=ResetReadiness.ResetReadiness
        EV_SetPtoStatus: start-on-event=RE_SetPtoStatus, operation=PowerTakeOffStatus.SetPtoStatus
      port-api-options:
        {enable-take-address=false, indirect-api=false, port-defined-argument-value{value=DemConf_DemEventParameter_DTC_0x000001_Event, value-type=Dem_EventIdType}, port=Event_DTC_0x000001_Event}
        {enable-take-address=false, indirect-api=false, port-defined-argument-value{value=DemConf_DemEventParameter_DTC_0x000001_Event, value-type=Dem_EventIdType}, port=EvtInfo_DTC_0x000001_Event}
        {enable-take-address=false, indirect-api=false, port-defined-argument-value{value=DemConf_DemEventParameter_Permanent_DTC, value-type=Dem_EventIdType}, port=Event_Permanent_DTC}
        {enable-take-address=false, indirect-api=false, port-defined-argument-value{value=DemConf_DemEventParameter_Permanent_DTC, value-type=Dem_EventIdType}, port=EvtInfo_Permanent_DTC}
        {enable-take-address=false, indirect-api=false, port-defined-argument-value{value=DemConf_DemEventParameter_CANSM_E_BUS_OFF_0, value-type=Dem_EventIdType}, port=EvtInfo_CANSM_E_BUS_OFF_0}
        {enable-take-address=false, indirect-api=false, port-defined-argument-value{value=DemConf_DemEventParameter_WDGM_E_MONITORING, value-type=Dem_EventIdType}, port=EvtInfo_WDGM_E_MONITORING}
        {enable-take-address=false, indirect-api=false, port-defined-argument-value{value=DemConf_DemEventParameter_WDGM_E_SET_MODE, value-type=Dem_EventIdType}, port=EvtInfo_WDGM_E_SET_MODE}
        {enable-take-address=false, indirect-api=false, port-defined-argument-value{value=DemConf_DemEventParameter_WDGM_E_DATA_CORRUPTION, value-type=Dem_EventIdType}, port=EvtInfo_WDGM_E_DATA_CORRUPTION}
        {enable-take-address=false, indirect-api=false, port-defined-argument-value{value=DemConf_DemEventParameter_ECUM_E_RAM_CHECK_FAILED, value-type=Dem_EventIdType}, port=EvtInfo_ECUM_E_RAM_CHECK_FAILED}
        {enable-take-address=false, indirect-api=false, port-defined-argument-value{value=DemConf_DemEventParameter_MCU_E_CLOCK_FAILURE, value-type=Dem_EventIdType}, port=EvtInfo_MCU_E_CLOCK_FAILURE}
        {enable-take-address=false, indirect-api=false, port-defined-argument-value{value=DemConf_DemEventParameter_WDGM_E_MF_TIMINGVIOLATION, value-type=Dem_EventIdType}, port=EvtInfo_WDGM_E_MF_TIMINGVIOLATION}
        {enable-take-address=false, indirect-api=false, port-defined-argument-value{value=DemConf_DemEventParameter_DTC_0x000002_Event, value-type=Dem_EventIdType}, port=Event_DTC_0x000002_Event}
        {enable-take-address=false, indirect-api=false, port-defined-argument-value{value=DemConf_DemEventParameter_DTC_0x000002_Event, value-type=Dem_EventIdType}, port=EvtInfo_DTC_0x000002_Event}
        {enable-take-address=false, indirect-api=false, port-defined-argument-value{value=DemConf_DemEventParameter_USER_DEFINE_MEMORY_Event, value-type=Dem_EventIdType}, port=Event_USER_DEFINE_MEMORY_Event}
        {enable-take-address=false, indirect-api=false, port-defined-argument-value{value=DemConf_DemEventParameter_USER_DEFINE_MEMORY_Event, value-type=Dem_EventIdType}, port=EvtInfo_USER_DEFINE_MEMORY_Event}
        {enable-take-address=false, indirect-api=false, port-defined-argument-value{value=DemConf_DemEventParameter_MCU_E_TIMEOUT_FAILURE, value-type=Dem_EventIdType}, port=EvtInfo_MCU_E_TIMEOUT_FAILURE}
        {enable-take-address=false, indirect-api=false, port-defined-argument-value{value=DemConf_DemEventParameter_MCU_E_INVALIDFXOSC_CONFIG, value-type=Dem_EventIdType}, port=EvtInfo_MCU_E_INVALIDFXOSC_CONFIG}
        {enable-take-address=false, indirect-api=false, port-defined-argument-value{value=DemConf_DemEventParameter_MCU_E_CLOCKMUXSWITCH_FAILURE, value-type=Dem_EventIdType}, port=EvtInfo_MCU_E_CLOCKMUXSWITCH_FAILURE}
        {enable-take-address=false, indirect-api=false, port-defined-argument-value{value=DEM_OPCYC_IGNITION, value-type=Dem_OperationCycleIdType}, port=OpCycle_DEM_OPCYC_IGNITION}
        {enable-take-address=false, indirect-api=false, port-defined-argument-value{value=DEM_OPCYC_OBD_DCY, value-type=Dem_OperationCycleIdType}, port=OpCycle_DEM_OPCYC_OBD_DCY}
        {enable-take-address=false, indirect-api=false, port-defined-argument-value{value=DEM_OPCYC_POWER, value-type=Dem_OperationCycleIdType}, port=OpCycle_DEM_OPCYC_POWER}
        {enable-take-address=false, indirect-api=false, port-defined-argument-value{value=0, value-type=uint8}, port=EnableCond_DEM_SL_ECU_LEVEL}
        {enable-take-address=false, indirect-api=false, port-defined-argument-value{value=DemConf_DemIndicator_DEM_INDICATOR_0, value-type=Dem_IndicatorIdType}, port=IndStatus_DEM_INDICATOR_0}
        {enable-take-address=false, indirect-api=false, port-defined-argument-value{value=DEM_DTC_ORIGIN_PRIMARY_MEMORY, value-type=Dem_DTCOriginType}, port=OverflowIndPrimaryMemory}
        {enable-take-address=false, indirect-api=false, port-defined-argument-value{value=DEM_DTC_ORIGIN_SECONDARY_MEMORY, value-type=Dem_DTCOriginType}, port=OverflowIndSecondaryMemory}
        {enable-take-address=false, indirect-api=false, port-defined-argument-value{value=DEM_DTC_ORIGIN_PERMANENT_MEMORY, value-type=Dem_DTCOriginType}, port=OverflowIndPermanentMemory}
        enable-take-address=true, indirect-api=false, port=CBReadData_DemExternalCSDataElementClass_Session
        enable-take-address=true, indirect-api=false, port=CBReadData_DemExternalCSDataElementClass_ExtDataRec_0x01
      29 x runnable:
        RE_GetDTCOfEvent: arguments=[symbol=EventId, symbol=DTCFormat, symbol=DTCOfEvent], can-be-invoked-concurrently=true, symbol=Dem_GetDTCOfEvent
        RE_GetEventFreezeFrameData: arguments=[symbol=EventId, symbol=RecordNumber, symbol=ReportTotalRecord, symbol=DataId, symbol=DestBuffer], can-be-invoked-concurrently=true, symbol=Dem_ASR42_GetEventFreezeFrameData
        RE_SetDTCSuppression: arguments=[symbol=DTC, symbol=DTCFormat, symbol=SuppressionStatus], symbol=Dem_SetDTCSuppression
        RE_CddIfClearDTC: symbol=Dem_ASR42_ClearDTC
        RE_SetEventStatus: arguments=[symbol=EventId, symbol=EventStatus], can-be-invoked-concurrently=true, symbol=Dem_SetEventStatus
        RE_ResetEventStatus: runnable-entity-argument=symbol=EventId, can-be-invoked-concurrently=true, symbol=Dem_ResetEventStatus
        RE_PrestoreFreezeFrame: runnable-entity-argument=symbol=EventId, can-be-invoked-concurrently=true, symbol=Dem_PrestoreFreezeFrame
          sync call sscp_CBReadDataDemExternalCSDataElementClass_Session: operation=CBReadData_DemExternalCSDataElementClass_Session.ReadData, timeout=0.0
          sync call sscp_CBReadDataDemExternalCSDataElementClass_ExtDataRec_0x01: operation=CBReadData_DemExternalCSDataElementClass_ExtDataRec_0x01.ReadData, timeout=0.0
        RE_ClearPrestoredFreezeFrame: runnable-entity-argument=symbol=EventId, can-be-invoked-concurrently=true, symbol=Dem_ClearPrestoredFreezeFrame
        RE_SetEventDisabled: runnable-entity-argument=symbol=EventId, can-be-invoked-concurrently=true, symbol=Dem_SetEventDisabled
        RE_ResetEventDebounceStatus: arguments=[symbol=EventId, symbol=DebounceResetStatus], can-be-invoked-concurrently=true, symbol=Dem_ResetEventDebounceStatus
        RE_GetEventStatus: arguments=[symbol=EventId, symbol=EventStatusExtended], can-be-invoked-concurrently=true, symbol=Dem_GetEventStatus
        RE_GetEventFailed: arguments=[symbol=EventId, symbol=EventFailed], can-be-invoked-concurrently=true, symbol=Dem_GetEventFailed
        RE_GetEventTested: arguments=[symbol=EventId, symbol=EventTested], can-be-invoked-concurrently=true, symbol=Dem_GetEventTested
        RE_GetFaultDetectionCounter: arguments=[symbol=EventId, symbol=FaultDetectionCounter], can-be-invoked-concurrently=true, symbol=Dem_GetFaultDetectionCounter
        RE_GetEventExtendedDataRecord: arguments=[symbol=EventId, symbol=RecordNumber, symbol=DestBuffer], can-be-invoked-concurrently=true, symbol=Dem_GetEventExtendedDataRecord
        RE_GetDebouncingOfEvent: arguments=[symbol=EventId, symbol=DebouncingState], can-be-invoked-concurrently=true, symbol=Dem_GetDebouncingOfEvent
        RE_GetEventFreezeFrameDataEx: arguments=[symbol=EventId, symbol=RecordNumber, symbol=DataId, symbol=DestBuffer, symbol=BufSize], can-be-invoked-concurrently=true, symbol=Dem_GetEventFreezeFrameDataEx
        RE_GetEventExtendedDataRecordEx: arguments=[symbol=EventId, symbol=RecordNumber, symbol=DestBuffer, symbol=BufSize], can-be-invoked-concurrently=true, symbol=Dem_GetEventExtendedDataRecordEx
        RE_SetOperationCycleState: arguments=[symbol=OperationCycleId, symbol=CycleState], can-be-invoked-concurrently=true, symbol=Dem_SetOperationCycleState
        RE_SetCycleQualified: runnable-entity-argument=symbol=OperationCycleId, can-be-invoked-concurrently=true, symbol=Dem_SetCycleQualified
        RE_SetEnableCondition: arguments=[symbol=EnableConditionID, symbol=ConditionFulfilled], can-be-invoked-concurrently=true, symbol=Dem_SetEnableCondition
        RE_GetIndicatorStatus: arguments=[symbol=IndicatorId, symbol=IndicatorStatus], can-be-invoked-concurrently=true, symbol=Dem_GetIndicatorStatus
        RE_GetEventMemoryOverflow: arguments=[symbol=DTCOrigin, symbol=OverflowIndication], can-be-invoked-concurrently=true, symbol=Dem_GetEventMemoryOverflow
        RE_GetNumberOfEventMemoryEntries: arguments=[symbol=DTCOrigin, symbol=NumberOfEventMemoryEntries], can-be-invoked-concurrently=true, symbol=Dem_GetNumberOfEventMemoryEntries
        RE_SetPfcCycleQualified: can-be-invoked-concurrently=true, symbol=Dem_SetPfcCycleQualified
        RE_GetPfcCycleQualified: can-be-invoked-concurrently=true, symbol=Dem_GetPfcCycleQualified
        RE_ResetReadiness: can-be-invoked-concurrently=true, symbol=Dem_ResetReadiness
        RE_SetPtoStatus: can-be-invoked-concurrently=true, symbol=Dem_SetPtoStatus
        RE_MainFunction: symbol=Dem_MainFunction
          sync call sscp_CBReadDataDemExternalCSDataElementClass_Session: operation=CBReadData_DemExternalCSDataElementClass_Session.ReadData, timeout=0.0
          sync call sscp_CBReadDataDemExternalCSDataElementClass_ExtDataRec_0x01: operation=CBReadData_DemExternalCSDataElementClass_ExtDataRec_0x01.ReadData, timeout=0.0
          sync call sscp_SetClearDTC_master: operation=SetClearDTC_master.SetClearDTC, timeout=0.0
package /EB_Dem/SwcImplementations
  swc implementation DemImpl: programming-language=C, sw-version=6.4.5, vendor-id=1, behavior=DemIntBeh
    code-descriptors:
      code DemCode: artifact-descriptors=autosar-engineering-object={short-label=EngObject, category=SWSRC}
    resource consumption Resources
      memory section CODE: sw-addrmethod=CODE
